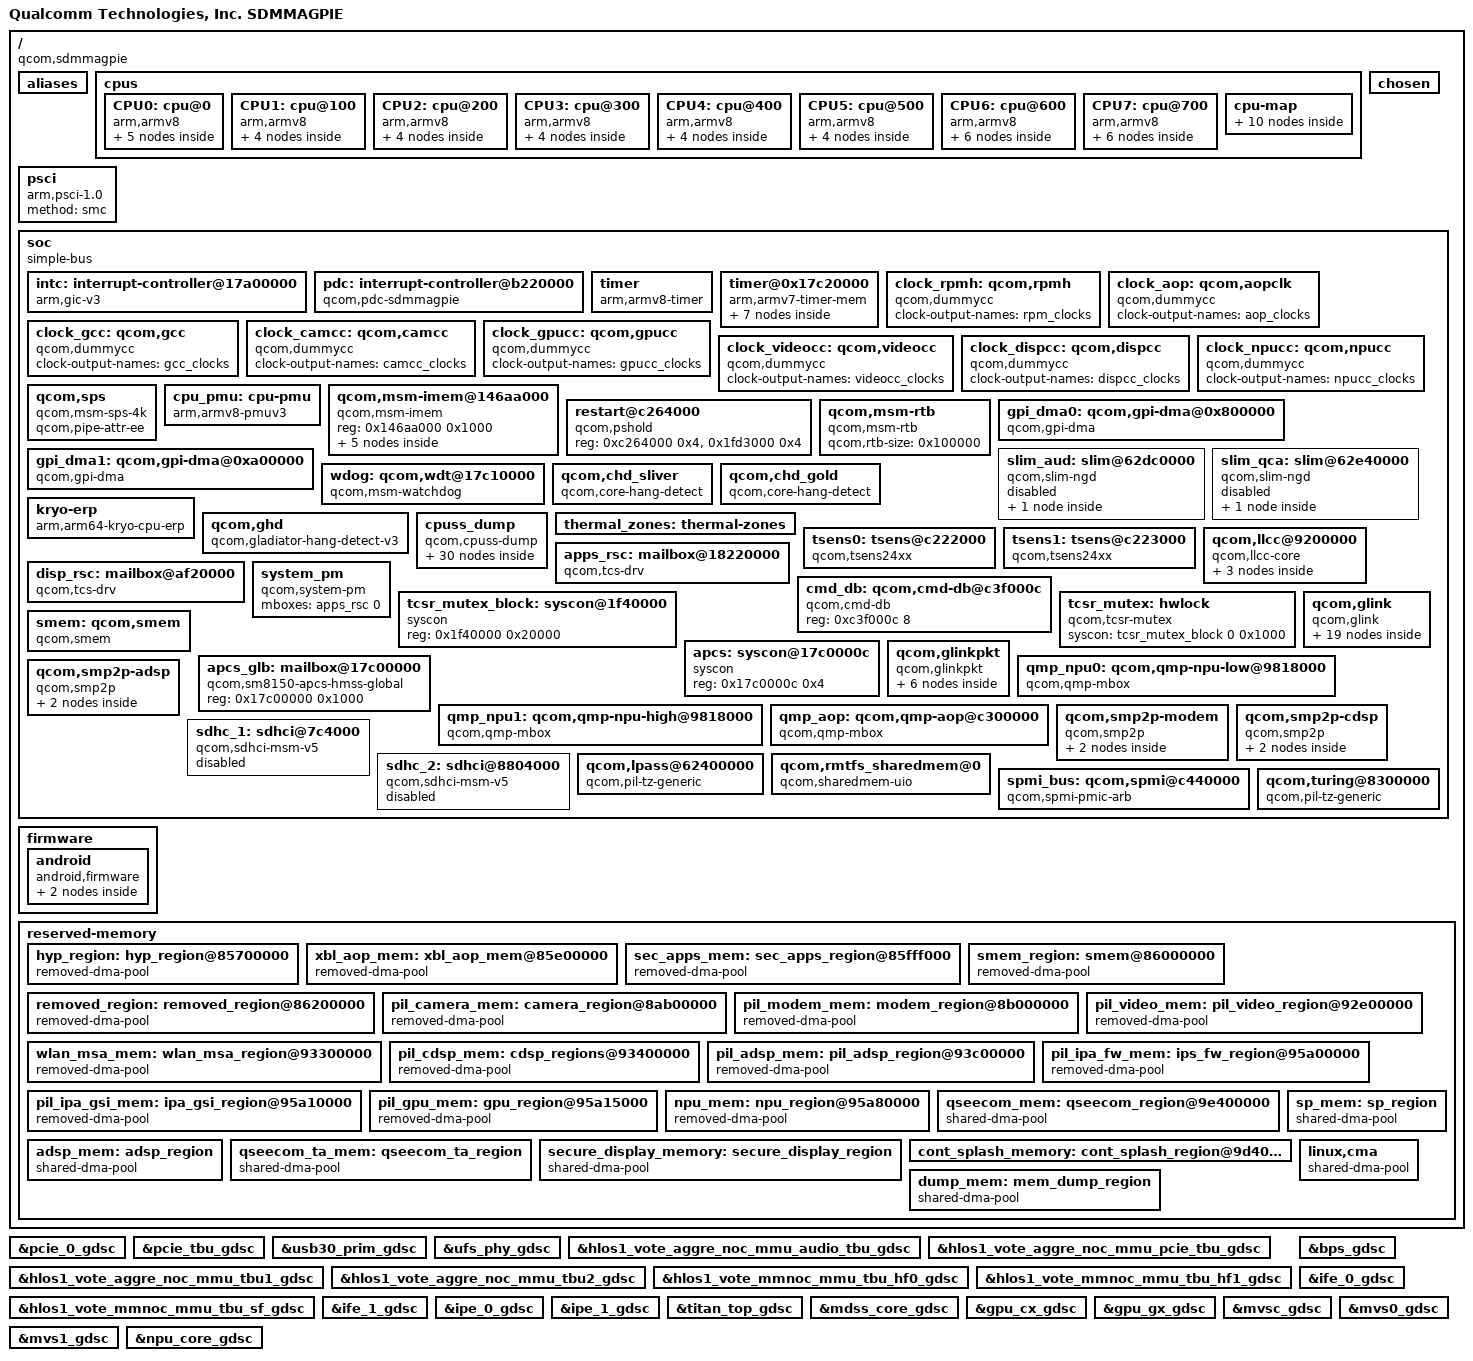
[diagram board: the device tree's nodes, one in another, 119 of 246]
/* Copyright (c) 2018, The Linux Foundation. All rights reserved.
 *
 * This program is free software; you can redistribute it and/or modify
 * it under the terms of the GNU General Public License version 2 and
 * only version 2 as published by the Free Software Foundation.
 *
 * This program is distributed in the hope that it will be useful,
 * but WITHOUT ANY WARRANTY; without even the implied warranty of
 * MERCHANTABILITY or FITNESS FOR A PARTICULAR PURPOSE.  See the
 * GNU General Public License for more details.
 */

#include "skeleton64.dtsi"
#include <dt-bindings/interrupt-controller/arm-gic.h>
#include <dt-bindings/clock/qcom,gcc-sdmmagpie.h>
#include <dt-bindings/clock/qcom,gpucc-sdmmagpie.h>
#include <dt-bindings/clock/qcom,camcc-sdmmagpie.h>
#include <dt-bindings/clock/qcom,videocc-sdmmagpie.h>
#include <dt-bindings/clock/qcom,dispcc-sdmmagpie.h>
#include <dt-bindings/clock/qcom,npucc-sdmmagpie.h>
#include <dt-bindings/clock/qcom,rpmh.h>
#include <dt-bindings/clock/qcom,aop-qmp.h>
#include <dt-bindings/regulator/qcom,rpmh-regulator.h>
#include <dt-bindings/soc/qcom,tcs-mbox.h>

/ {
	model = "Qualcomm Technologies, Inc. SDMMAGPIE";
	compatible = "qcom,sdmmagpie";
	qcom,msm-id = <365 0x0>;
	interrupt-parent = <&pdc>;

	aliases {
		spi0 = &qupv3_se0_spi;
		spi1 = &qupv3_se4_spi;
		i2c0 = &qupv3_se2_i2c;
		i2c1 = &qupv3_se7_i2c;
		i2c2 = &qupv3_se9_i2c;
		serial0 = &qupv3_se8_2uart;
		hsuart0 = &qupv3_se3_4uart;
		sdhc1 = &sdhc_1; /* SDC1 eMMC slot */
		sdhc2 = &sdhc_2; /* SDC2 SD Card slot */
	};

	cpus {
		#address-cells = <2>;
		#size-cells = <0>;

		CPU0: cpu@0 {
			device_type = "cpu";
			compatible = "arm,armv8";
			reg = <0x0 0x0>;
			enable-method = "psci";
			cache-size = <0x8000>;
			next-level-cache = <&L2_0>;
			L2_0: l2-cache {
			      compatible = "arm,arch-cache";
			      cache-size = <0x20000>;
			      cache-level = <2>;
			      next-level-cache = <&L3_0>;

				L3_0: l3-cache {
				      compatible = "arm,arch-cache";
				      cache-size = <0x100000>;
				      cache-level = <3>;
				};
			};

			L1_I_0: l1-icache {
				compatible = "arm,arch-cache";
				qcom,dump-size = <0x8800>;
			};

			L1_D_0: l1-dcache {
				compatible = "arm,arch-cache";
				qcom,dump-size = <0x9000>;
			};

			L2_TLB_0: l2-tlb {
				qcom,dump-size = <0x5000>;
			};
		};

		CPU1: cpu@100 {
			device_type = "cpu";
			compatible = "arm,armv8";
			reg = <0x0 0x100>;
			enable-method = "psci";
			cache-size = <0x8000>;
			next-level-cache = <&L2_100>;
			L2_100: l2-cache {
			      compatible = "arm,arch-cache";
			      cache-size = <0x20000>;
			      cache-level = <2>;
			      next-level-cache = <&L3_0>;
			};

			L1_I_100: l1-icache {
				compatible = "arm,arch-cache";
				qcom,dump-size = <0x8800>;
			};

			L1_D_100: l1-dcache {
				compatible = "arm,arch-cache";
				qcom,dump-size = <0x9000>;
			};

			L2_TLB_100: l2-tlb {
				qcom,dump-size = <0x5000>;
			};
		};


		CPU2: cpu@200 {
			device_type = "cpu";
			compatible = "arm,armv8";
			reg = <0x0 0x200>;
			enable-method = "psci";
			cache-size = <0x8000>;
			next-level-cache = <&L2_200>;
			L2_200: l2-cache {
			      compatible = "arm,arch-cache";
			      cache-size = <0x20000>;
			      cache-level = <2>;
			      next-level-cache = <&L3_0>;
			};

			L1_I_200: l1-icache {
				compatible = "arm,arch-cache";
				qcom,dump-size = <0x8800>;
			};

			L1_D_200: l1-dcache {
				compatible = "arm,arch-cache";
				qcom,dump-size = <0x9000>;
			};

			L2_TLB_200: l2-tlb {
				qcom,dump-size = <0x5000>;
			};
		};

		CPU3: cpu@300 {
			device_type = "cpu";
			compatible = "arm,armv8";
			reg = <0x0 0x300>;
			enable-method = "psci";
			cache-size = <0x8000>;
			next-level-cache = <&L2_300>;
			L2_300: l2-cache {
			      compatible = "arm,arch-cache";
			      cache-size = <0x20000>;
			      cache-level = <2>;
			      next-level-cache = <&L3_0>;
			};

			L1_I_300: l1-icache {
				compatible = "arm,arch-cache";
				qcom,dump-size = <0x8800>;
			};

			L1_D_300: l1-dcache {
				compatible = "arm,arch-cache";
				qcom,dump-size = <0x9000>;
			};

			L2_TLB_300: l2-tlb {
				qcom,dump-size = <0x5000>;
			};
		};

		CPU4: cpu@400 {
			device_type = "cpu";
			compatible = "arm,armv8";
			reg = <0x0 0x400>;
			enable-method = "psci";
			cache-size = <0x8000>;
			next-level-cache = <&L2_400>;
			L2_400: l2-cache {
			      compatible = "arm,arch-cache";
			      cache-size = <0x20000>;
			      cache-level = <2>;
			      next-level-cache = <&L3_0>;
			};

			L1_I_400: l1-icache {
				compatible = "arm,arch-cache";
				qcom,dump-size = <0x8800>;
			};

			L1_D_400: l1-dcache {
				compatible = "arm,arch-cache";
				qcom,dump-size = <0x9000>;
			};

			L2_TLB_400: l2-tlb {
				qcom,dump-size = <0x5000>;
			};
		};

		CPU5: cpu@500 {
			device_type = "cpu";
			compatible = "arm,armv8";
			reg = <0x0 0x500>;
			enable-method = "psci";
			cache-size = <0x8000>;
			next-level-cache = <&L2_500>;
			L2_500: l2-cache {
			      compatible = "arm,arch-cache";
			      cache-size = <0x20000>;
			      cache-level = <2>;
			      next-level-cache = <&L3_0>;
			};

			L1_I_500: l1-icache {
				compatible = "arm,arch-cache";
				qcom,dump-size = <0x8800>;
			};

			L1_D_500: l1-dcache {
				compatible = "arm,arch-cache";
				qcom,dump-size = <0x9000>;
			};

			L2_TLB_500: l2-tlb {
				qcom,dump-size = <0x5000>;
			};
		};

		CPU6: cpu@600 {
			device_type = "cpu";
			compatible = "arm,armv8";
			reg = <0x0 0x600>;
			enable-method = "psci";
			cache-size = <0x10000>;
			next-level-cache = <&L2_600>;
			L2_600: l2-cache {
			      compatible = "arm,arch-cache";
			      cache-size = <0x40000>;
			      cache-level = <2>;
			      next-level-cache = <&L3_0>;
			      qcom,dump-size = <0x48000>;
			};

			L1_I_600: l1-icache {
				compatible = "arm,arch-cache";
				qcom,dump-size = <0x11000>;
			};

			L1_D_600: l1-dcache {
				compatible = "arm,arch-cache";
				qcom,dump-size = <0x12000>;
			};

			L1_ITLB_600: l1-itlb {
				qcom,dump-size = <0x300>;
			};

			L1_DTLB_600: l1-dtlb {
				qcom,dump-size = <0x480>;
			};

			L2_TLB_600: l2-tlb {
				qcom,dump-size = <0x7800>;
			};
		};

		CPU7: cpu@700 {
			device_type = "cpu";
			compatible = "arm,armv8";
			reg = <0x0 0x700>;
			enable-method = "psci";
			cache-size = <0x10000>;
			next-level-cache = <&L2_700>;
			L2_700: l2-cache {
			      compatible = "arm,arch-cache";
			      cache-size = <0x40000>;
			      cache-level = <2>;
			      next-level-cache = <&L3_0>;
			      qcom,dump-size = <0x48000>;
			};

			L1_I_700: l1-icache {
				compatible = "arm,arch-cache";
				qcom,dump-size = <0x11000>;
			};

			L1_D_700: l1-dcache {
				compatible = "arm,arch-cache";
				qcom,dump-size = <0x12000>;
			};

			L1_ITLB_700: l1-itlb {
				qcom,dump-size = <0x300>;
			};

			L1_DTLB_700: l1-dtlb {
				qcom,dump-size = <0x480>;
			};

			L2_TLB_700: l2-tlb {
				qcom,dump-size = <0x7800>;
			};
		};

		cpu-map {
			cluster0 {
				core0 {
					cpu = <&CPU0>;
				};

				core1 {
					cpu = <&CPU1>;
				};

				core2 {
					cpu = <&CPU2>;
				};

				core3 {
					cpu = <&CPU3>;
				};

				core4 {
					cpu = <&CPU4>;
				};

				core5 {
					cpu = <&CPU5>;
				};

			};

			cluster1 {
				core6 {
					cpu = <&CPU6>;
				};

				core7 {
					cpu = <&CPU7>;
				};
			};
		};
	};

	psci {
		compatible = "arm,psci-1.0";
		method = "smc";
	};

	chosen {
		bootargs = "rcupdate.rcu_expedited=1 rcu_nocbs=0-7";
	};

	soc: soc { };

	firmware: firmware {
		android {
			compatible = "android,firmware";
			fstab {
				compatible = "android,fstab";
				vendor {
					compatible = "android,vendor";
					dev = "/dev/block/platform/soc/1d84000.ufshc/by-name/vendor";
					type = "ext4";
					mnt_flags = "ro,barrier=1,discard";
					fsmgr_flags = "wait,slotselect,avb";
					status = "ok";
				};
			};
		};
	};

	reserved-memory {
		#address-cells = <2>;
		#size-cells = <2>;
		ranges;

		hyp_region: hyp_region@85700000 {
			compatible = "removed-dma-pool";
			no-map;
			reg = <0 0x85700000 0 0x600000>;
		};

		xbl_aop_mem: xbl_aop_mem@85e00000 {
			compatible = "removed-dma-pool";
			no-map;
			reg = <0x0 0x85e00000 0x0 0x1ff000>;
		};

		sec_apps_mem: sec_apps_region@85fff000 {
			compatible = "removed-dma-pool";
			no-map;
			reg = <0x0 0x85fff000 0x0 0x1000>;
		};

		smem_region: smem@86000000 {
			compatible = "removed-dma-pool";
			no-map;
			reg = <0x0 0x86000000 0x0 0x200000>;
		};

		removed_region: removed_region@86200000 {
			compatible = "removed-dma-pool";
			no-map;
			reg = <0 0x86200000 0 0x2d00000>;
		};

		pil_camera_mem: camera_region@8ab00000 {
			compatible = "removed-dma-pool";
			no-map;
			reg = <0 0x8ab00000 0 0x500000>;
		};

		pil_modem_mem: modem_region@8b000000 {
			compatible = "removed-dma-pool";
			no-map;
			reg = <0 0x8b000000 0 0x7e00000>;
		};

		pil_video_mem: pil_video_region@92e00000 {
			compatible = "removed-dma-pool";
			no-map;
			reg = <0 0x92e00000 0 0x500000>;
		};

		wlan_msa_mem: wlan_msa_region@93300000 {
			compatible = "removed-dma-pool";
			no-map;
			reg = <0 0x93300000 0 0x100000>;
		};

		pil_cdsp_mem: cdsp_regions@93400000 {
			compatible = "removed-dma-pool";
			no-map;
			reg = <0 0x93400000 0 0x800000>;
		};

		pil_adsp_mem: pil_adsp_region@93c00000 {
			compatible = "removed-dma-pool";
			no-map;
			reg = <0 0x93c00000 0 0x1e00000>;
		};

		pil_ipa_fw_mem: ips_fw_region@95a00000 {
			compatible = "removed-dma-pool";
			no-map;
			reg = <0 0x95a00000 0 0x10000>;
		};

		pil_ipa_gsi_mem: ipa_gsi_region@95a10000 {
			compatible = "removed-dma-pool";
			no-map;
			reg = <0 0x95a10000 0 0x5000>;
		};

		pil_gpu_mem: gpu_region@95a15000 {
			compatible = "removed-dma-pool";
			no-map;
			reg = <0 0x95a15000 0 0x2000>;
		};

		npu_mem: npu_region@95a80000 {
			compatible = "removed-dma-pool";
			no-map;
			reg = <0 0x95a80000 0 0x80000>;
		};

		qseecom_mem: qseecom_region@9e400000 {
			compatible = "shared-dma-pool";
			no-map;
			reg = <0 0x9e400000 0 0x1400000>;
		};

		adsp_mem: adsp_region {
			compatible = "shared-dma-pool";
			alloc-ranges = <0 0x00000000 0 0xffffffff>;
			reusable;
			alignment = <0 0x400000>;
			size = <0 0xc00000>;
		};

		qseecom_ta_mem: qseecom_ta_region {
			compatible = "shared-dma-pool";
			alloc-ranges = <0 0x00000000 0 0xffffffff>;
			reusable;
			alignment = <0 0x400000>;
			size = <0 0x1000000>;
		};

		sp_mem: sp_region {  /* SPSS-HLOS ION shared mem */
			compatible = "shared-dma-pool";
			alloc-ranges = <0 0x00000000 0 0xffffffff>; /* 32-bit */
			reusable;
			alignment = <0 0x400000>;
			size = <0 0x800000>;
		};

		secure_display_memory: secure_display_region {
			compatible = "shared-dma-pool";
			alloc-ranges = <0 0x00000000 0 0xffffffff>;
			reusable;
			alignment = <0 0x400000>;
			size = <0 0x5c00000>;
		};

		cont_splash_memory: cont_splash_region@9d400000 {
			reg = <0x0 0x9d400000 0x0 0x02400000>;
			label = "cont_splash_region";
		};

		dump_mem: mem_dump_region {
			compatible = "shared-dma-pool";
			reusable;
			size = <0 0x2400000>;
		};

		/* global autoconfigured region for contiguous allocations */
		linux,cma {
			compatible = "shared-dma-pool";
			alloc-ranges = <0 0x00000000 0 0xffffffff>;
			reusable;
			alignment = <0 0x400000>;
			size = <0 0x2000000>;
			linux,cma-default;
		};
	};
};

&soc {
	#address-cells = <1>;
	#size-cells = <1>;
	ranges = <0 0 0 0xffffffff>;
	compatible = "simple-bus";

	intc: interrupt-controller@17a00000 {
		compatible = "arm,gic-v3";
		#interrupt-cells = <3>;
		interrupt-controller;
		#redistributor-regions = <1>;
		redistributor-stride = <0x0 0x20000>;
		reg = <0x17a00000 0x10000>,     /* GICD */
		      <0x17a60000 0x100000>;    /* GICR * 8 */
		interrupts = <GIC_PPI 9 IRQ_TYPE_LEVEL_HIGH>;
		interrupt-parent = <&intc>;
	};

	pdc: interrupt-controller@b220000 {
		compatible = "qcom,pdc-sdmmagpie";
		reg = <0xb220000 0x400>;
		#interrupt-cells = <3>;
		interrupt-parent = <&intc>;
		interrupt-controller;
	};

	timer {
		compatible = "arm,armv8-timer";
		interrupts = <GIC_PPI 1 0xf08>,
			     <GIC_PPI 2 0xf08>,
			     <GIC_PPI 3 0xf08>,
			     <GIC_PPI 0 0xf08>;
		clock-frequency = <19200000>;
	};

	timer@0x17c20000{
		#address-cells = <1>;
		#size-cells = <1>;
		ranges;
		compatible = "arm,armv7-timer-mem";
		reg = <0x17c20000 0x1000>;
		clock-frequency = <19200000>;

		frame@0x17c21000 {
			frame-number = <0>;
			interrupts = <GIC_SPI 8 IRQ_TYPE_LEVEL_HIGH>,
				     <GIC_SPI 6 IRQ_TYPE_LEVEL_HIGH>;
			reg = <0x17c21000 0x1000>,
			      <0x17c22000 0x1000>;
		};

		frame@17c23000 {
			frame-number = <1>;
			interrupts = <GIC_SPI 9 IRQ_TYPE_LEVEL_HIGH>;
			reg = <0x17c23000 0x1000>;
			status = "disabled";
		};

		frame@17c25000 {
			frame-number = <2>;
			interrupts = <GIC_SPI 10 IRQ_TYPE_LEVEL_HIGH>;
			reg = <0x17c25000 0x1000>;
			status = "disabled";
		};

		frame@17c27000 {
			frame-number = <3>;
			interrupts = <GIC_SPI 11 IRQ_TYPE_LEVEL_HIGH>;
			reg = <0x17c27000 0x1000>;
			status = "disabled";
		};

		frame@17c29000 {
			frame-number = <4>;
			interrupts = <GIC_SPI 12 IRQ_TYPE_LEVEL_HIGH>;
			reg = <0x17c29000 0x1000>;
			status = "disabled";
		};

		frame@17c2b000 {
			frame-number = <5>;
			interrupts = <GIC_SPI 13 IRQ_TYPE_LEVEL_HIGH>;
			reg = <0x17c2b000 0x1000>;
			status = "disabled";
		};

		frame@17c2d000 {
			frame-number = <6>;
			interrupts = <GIC_SPI 14 IRQ_TYPE_LEVEL_HIGH>;
			reg = <0x17c2d000 0x1000>;
			status = "disabled";
		};
	};

	clock_rpmh: qcom,rpmh {
		compatible = "qcom,dummycc";
		clock-output-names = "rpm_clocks";
		#clock-cells = <1>;
	};

	clock_aop: qcom,aopclk {
		compatible = "qcom,dummycc";
		clock-output-names = "aop_clocks";
		#clock-cells = <1>;
	};

	clock_gcc: qcom,gcc {
		compatible = "qcom,dummycc";
		clock-output-names = "gcc_clocks";
		#clock-cells = <1>;
		#reset-cells = <1>;
	};

	clock_camcc: qcom,camcc {
		compatible = "qcom,dummycc";
		clock-output-names = "camcc_clocks";
		#clock-cells = <1>;
		#reset-cells = <1>;
	};

	clock_gpucc: qcom,gpucc {
		compatible = "qcom,dummycc";
		clock-output-names = "gpucc_clocks";
		#clock-cells = <1>;
		#reset-cells = <1>;
	};

	clock_videocc: qcom,videocc {
		compatible = "qcom,dummycc";
		clock-output-names = "videocc_clocks";
		#clock-cells = <1>;
		#reset-cells = <1>;
	};

	clock_dispcc: qcom,dispcc {
		compatible = "qcom,dummycc";
		clock-output-names = "dispcc_clocks";
		#clock-cells = <1>;
		#reset-cells = <1>;
	};

	clock_npucc: qcom,npucc {
		compatible = "qcom,dummycc";
		clock-output-names = "npucc_clocks";
		#clock-cells = <1>;
		#reset-cells = <1>;
	};

	qcom,sps {
		compatible = "qcom,msm-sps-4k";
		qcom,pipe-attr-ee;
	};

	cpu_pmu: cpu-pmu {
		compatible = "arm,armv8-pmuv3";
		qcom,irq-is-percpu;
		interrupts = <GIC_PPI 5 IRQ_TYPE_LEVEL_HIGH>;
	};

	qcom,msm-imem@146aa000 {
		compatible = "qcom,msm-imem";
		reg = <0x146aa000 0x1000>;
		ranges = <0x0 0x146aa000 0x1000>;
		#address-cells = <1>;
		#size-cells = <1>;

		mem_dump_table@10 {
			compatible = "qcom,msm-imem-mem_dump_table";
			reg = <0x10 8>;
		};

		restart_reason@65c {
			compatible = "qcom,msm-imem-restart_reason";
			reg = <0x65c 4>;
		};

		boot_stats@6b0 {
			compatible = "qcom,msm-imem-boot_stats";
			reg = <0x6b0 32>;
		};

		kaslr_offset@6d0 {
			compatible = "qcom,msm-imem-kaslr_offset";
			reg = <0x6d0 12>;
		};

		pil@94c {
			compatible = "qcom,msm-imem-pil";
			reg = <0x94c 200>;
		};
	};

	restart@c264000 {
		compatible = "qcom,pshold";
		reg = <0xc264000 0x4>,
		      <0x1fd3000 0x4>;
		reg-names = "pshold-base", "tcsr-boot-misc-detect";
	};

	qcom,msm-rtb {
		compatible = "qcom,msm-rtb";
		qcom,rtb-size = <0x100000>;
	};

	gpi_dma0: qcom,gpi-dma@0x800000 {
		#dma-cells = <5>;
		compatible = "qcom,gpi-dma";
		reg = <0x800000 0x60000>;
		reg-names = "gpi-top";
		interrupts = <0 244 0>, <0 245 0>, <0 246 0>, <0 247 0>,
			     <0 248 0>, <0 249 0>, <0 250 0>, <0 251 0>;
		qcom,max-num-gpii = <8>;
		qcom,gpii-mask = <0x0f>;
		qcom,ev-factor = <2>;
		iommus = <&apps_smmu 0x0216 0x0>;
		qcom,smmu-cfg = <0x1>;
		qcom,iova-range = <0x0 0x100000 0x0 0x100000>;
		status = "ok";
	};

	gpi_dma1: qcom,gpi-dma@0xa00000 {
		#dma-cells = <5>;
		compatible = "qcom,gpi-dma";
		reg = <0xa00000 0x60000>;
		reg-names = "gpi-top";
		interrupts = <0 279 0>, <0 280 0>, <0 281 0>, <0 282 0>,
		     <0 283 0>, <0 284 0>, <0 293 0>, <0 294 0>;
		qcom,max-num-gpii = <8>;
		qcom,gpii-mask = <0x0f>;
		qcom,ev-factor = <2>;
		iommus = <&apps_smmu 0x04d6 0x0>;
		qcom,smmu-cfg = <0x1>;
		qcom,iova-range = <0x0 0x100000 0x0 0x100000>;
		status = "ok";
	};

	slim_aud: slim@62dc0000 {
		cell-index = <1>;
		compatible = "qcom,slim-ngd";
		reg = <0x62dc0000 0x2c000>,
			<0x62d84000 0x2a000>;
		reg-names = "slimbus_physical", "slimbus_bam_physical";
		interrupts = <0 163 0>, <0 164 0>;
		interrupt-names = "slimbus_irq", "slimbus_bam_irq";
		qcom,apps-ch-pipes = <0x7c0000>;
		qcom,ea-pc = <0x300>;
		status = "disabled";
		qcom,iommu-s1-bypass;

		iommu_slim_aud_ctrl_cb: qcom,iommu_slim_ctrl_cb {
			compatible = "qcom,iommu-slim-ctrl-cb";
			iommus = <&apps_smmu 0x1be6 0x0>,
				 <&apps_smmu 0x1bed 0x0>,
				 <&apps_smmu 0x1bee 0x1>,
				 <&apps_smmu 0x1bf0 0x1>;
		};

	};

	slim_qca: slim@62e40000 {
		cell-index = <3>;
		compatible = "qcom,slim-ngd";
		reg = <0x62e40000 0x2c000>,
			<0x62e04000 0x20000>;
		reg-names = "slimbus_physical", "slimbus_bam_physical";
		interrupts = <0 291 0>, <0 292 0>;
		interrupt-names = "slimbus_irq", "slimbus_bam_irq";
		status = "disabled";
		qcom,iommu-s1-bypass;

		iommu_slim_qca_ctrl_cb: qcom,iommu_slim_ctrl_cb {
			compatible = "qcom,iommu-slim-ctrl-cb";
			iommus = <&apps_smmu 0x1bf3 0x0>;
		};
	};

	wdog: qcom,wdt@17c10000{
		compatible = "qcom,msm-watchdog";
		reg = <0x17c10000 0x1000>;
		reg-names = "wdt-base";
		interrupts = <GIC_SPI 0 IRQ_TYPE_NONE>,
			     <GIC_SPI 1 IRQ_TYPE_NONE>;
		qcom,bark-time = <11000>;
		qcom,pet-time = <9360>;
		qcom,ipi-ping;
		qcom,wakeup-enable;
	};

	qcom,chd_sliver {
		compatible = "qcom,core-hang-detect";
		label = "silver";
		qcom,threshold-arr = <0x18000058 0x18010058
				      0x18020058 0x18030058
				      0x18040058 0x18050058>;
		qcom,config-arr = <0x18000060 0x18010060
				   0x18020060 0x18030060
				   0x18040060 0x18050060>;
	};

	qcom,chd_gold {
		compatible = "qcom,core-hang-detect";
		label = "gold";
		qcom,threshold-arr = <0x18060058 0x18070058>;
		qcom,config-arr = <0x18060060 0x18070060>;
	};

	kryo-erp {
		compatible = "arm,arm64-kryo-cpu-erp";
		interrupts = <GIC_PPI 6 IRQ_TYPE_LEVEL_HIGH>,
			     <GIC_SPI 35 IRQ_TYPE_LEVEL_HIGH>;

		interrupt-names = "l1-l2-faultirq",
				  "l3-scu-faultirq";
	};

	qcom,ghd {
		compatible = "qcom,gladiator-hang-detect-v3";
		qcom,threshold-arr = <0x17e0041C>;
		qcom,config-reg = <0x17e00434>;
	};

	cpuss_dump {
		compatible = "qcom,cpuss-dump";

		qcom,l1_i_cache0 {
			qcom,dump-node = <&L1_I_0>;
			qcom,dump-id = <0x60>;
		};

		qcom,l1_i_cache100 {
			qcom,dump-node = <&L1_I_100>;
			qcom,dump-id = <0x61>;
		};

		qcom,l1_i_cache200 {
			qcom,dump-node = <&L1_I_200>;
			qcom,dump-id = <0x62>;
		};

		qcom,l1_i_cache300 {
			qcom,dump-node = <&L1_I_300>;
			qcom,dump-id = <0x63>;
		};

		qcom,l1_i_cache400 {
			qcom,dump-node = <&L1_I_400>;
			qcom,dump-id = <0x64>;
		};

		qcom,l1_i_cache500 {
			qcom,dump-node = <&L1_I_500>;
			qcom,dump-id = <0x65>;
		};

		qcom,l1_i_cache600 {
			qcom,dump-node = <&L1_I_600>;
			qcom,dump-id = <0x66>;
		};

		qcom,l1_i_cache700 {
			qcom,dump-node = <&L1_I_700>;
			qcom,dump-id = <0x67>;
		};

		qcom,l1_d_cache0 {
			qcom,dump-node = <&L1_D_0>;
			qcom,dump-id = <0x80>;
		};

		qcom,l1_d_cache100 {
			qcom,dump-node = <&L1_D_100>;
			qcom,dump-id = <0x81>;
		};

		qcom,l1_d_cache200 {
			qcom,dump-node = <&L1_D_200>;
			qcom,dump-id = <0x82>;
		};

		qcom,l1_d_cache300 {
			qcom,dump-node = <&L1_D_300>;
			qcom,dump-id = <0x83>;
		};

		qcom,l1_d_cache400 {
			qcom,dump-node = <&L1_D_400>;
			qcom,dump-id = <0x84>;
		};

		qcom,l1_d_cache500 {
			qcom,dump-node = <&L1_D_500>;
			qcom,dump-id = <0x85>;
		};

		qcom,l1_d_cache600 {
			qcom,dump-node = <&L1_D_600>;
			qcom,dump-id = <0x86>;
		};

		qcom,l1_d_cache700 {
			qcom,dump-node = <&L1_D_700>;
			qcom,dump-id = <0x87>;
		};

		qcom,l1_i_tlb_dump600 {
			qcom,dump-node = <&L1_ITLB_600>;
			qcom,dump-id = <0x26>;
		};

		qcom,l1_i_tlb_dump700 {
			qcom,dump-node = <&L1_ITLB_700>;
			qcom,dump-id = <0x27>;
		};

		qcom,l1_d_tlb_dump600 {
			qcom,dump-node = <&L1_DTLB_600>;
			qcom,dump-id = <0x46>;
		};

		qcom,l1_d_tlb_dump700 {
			qcom,dump-node = <&L1_DTLB_700>;
			qcom,dump-id = <0x47>;
		};

		qcom,l2_cache_dump600 {
			qcom,dump-node = <&L2_600>;
			qcom,dump-id = <0xc6>;
		};

		qcom,l2_cache_dump700 {
			qcom,dump-node = <&L2_700>;
			qcom,dump-id = <0xc7>;
		};

		qcom,l2_tlb_dump0 {
			qcom,dump-node = <&L2_TLB_0>;
			qcom,dump-id = <0x120>;
		};

		qcom,l2_tlb_dump100 {
			qcom,dump-node = <&L2_TLB_100>;
			qcom,dump-id = <0x121>;
		};

		qcom,l2_tlb_dump200 {
			qcom,dump-node = <&L2_TLB_200>;
			qcom,dump-id = <0x122>;
		};

		qcom,l2_tlb_dump300 {
			qcom,dump-node = <&L2_TLB_300>;
			qcom,dump-id = <0x123>;
		};

		qcom,l2_tlb_dump400 {
			qcom,dump-node = <&L2_TLB_400>;
			qcom,dump-id = <0x124>;
		};

		qcom,l2_tlb_dump500 {
			qcom,dump-node = <&L2_TLB_500>;
			qcom,dump-id = <0x125>;
		};

		qcom,l2_tlb_dump600 {
			qcom,dump-node = <&L2_TLB_600>;
			qcom,dump-id = <0x126>;
		};

		qcom,l2_tlb_dump700 {
			qcom,dump-node = <&L2_TLB_700>;
			qcom,dump-id = <0x127>;
		};
	};

	thermal_zones: thermal-zones {};

	tsens0: tsens@c222000 {
		compatible = "qcom,tsens24xx";
		reg = <0xc222000 0x8>,
		      <0xc263000 0x1ff>;
		reg-names = "tsens_srot_physical",
			    "tsens_tm_physical";
		interrupts = <0 506 0>, <0 508 0>;
		interrupt-names = "tsens-upper-lower", "tsens-critical";
		#thermal-sensor-cells = <1>;
	};

	tsens1: tsens@c223000 {
		compatible = "qcom,tsens24xx";
		reg = <0xc223000 0x8>,
		      <0xc265000 0x1ff>;
		reg-names = "tsens_srot_physical",
			    "tsens_tm_physical";
		interrupts = <0 507 0>, <0 509 0>;
		interrupt-names = "tsens-upper-lower", "tsens-critical";
		#thermal-sensor-cells = <1>;
	};

	qcom,llcc@9200000 {
		compatible = "qcom,llcc-core", "syscon", "simple-mfd";
		reg = <0x9200000 0x450000>;
		reg-names = "llcc_base";
		qcom,llcc-banks-off = <0x0 0x80000>;
		qcom,llcc-broadcast-off = <0x400000>;

		llcc: qcom,sdmmagpie-llcc {
			compatible = "qcom,sdmmagpie-llcc";
			#cache-cells = <1>;
			max-slices = <32>;
			cap-based-alloc-and-pwr-collapse;
		};

		qcom,llcc-erp {
			compatible = "qcom,llcc-erp";
			interrupt-names = "ecc_irq";
			interrupts = <GIC_SPI 582 IRQ_TYPE_LEVEL_HIGH>;
		};

		qcom,llcc-amon {
			compatible = "qcom,llcc-amon";
		};
	};

	apps_rsc: mailbox@18220000 {
		compatible = "qcom,tcs-drv";
		label = "apps_rsc";
		reg = <0x18220000 0x100>, <0x18220d00 0x3000>;
		interrupts = <0 5 0>;
		#mbox-cells = <1>;
		qcom,drv-id = <2>;
		qcom,tcs-config = <ACTIVE_TCS  2>,
				  <SLEEP_TCS   3>,
				  <WAKE_TCS    3>,
				  <CONTROL_TCS 1>;
	};

	disp_rsc: mailbox@af20000 {
		compatible = "qcom,tcs-drv";
		label = "display_rsc";
		reg = <0xaf20000 0x100>, <0xaf21c00 0x3000>;
		interrupts = <0 129 0>;
		#mbox-cells = <1>;
		qcom,drv-id = <0>;
		qcom,tcs-config = <ACTIVE_TCS  2>,
				  <SLEEP_TCS   1>,
				  <WAKE_TCS    1>,
				  <CONTROL_TCS 0>;
	};

	system_pm {
		compatible = "qcom,system-pm";
		mboxes = <&apps_rsc 0>;
	};

	cmd_db: qcom,cmd-db@c3f000c {
		compatible = "qcom,cmd-db";
		reg = <0xc3f000c 8>;
	};

	tcsr_mutex_block: syscon@1f40000 {
		compatible = "syscon";
		reg = <0x1f40000 0x20000>;
	};

	tcsr_mutex: hwlock {
		compatible = "qcom,tcsr-mutex";
		syscon = <&tcsr_mutex_block 0 0x1000>;
		#hwlock-cells = <1>;
	};

	smem: qcom,smem {
		compatible = "qcom,smem";
		memory-region = <&smem_region>;
		hwlocks = <&tcsr_mutex 3>;
	};

	apcs: syscon@17c0000c {
		compatible = "syscon";
		reg = <0x17c0000c 0x4>;
	};

	apcs_glb: mailbox@17c00000 {
		compatible = "qcom,sm8150-apcs-hmss-global";
		reg = <0x17c00000 0x1000>;

		#mbox-cells = <1>;
	};

	qcom,glink {
		compatible = "qcom,glink";
		#address-cells = <1>;
		#size-cells = <1>;
		ranges;

		glink_modem: modem {
			qcom,remote-pid = <1>;
			transport = "smem";
			mboxes = <&apcs_glb 12>;
			mbox-names = "mpss_smem";
			interrupts = <GIC_SPI 449 IRQ_TYPE_EDGE_RISING>;

			label = "modem";
			qcom,glink-label = "mpss";

			qcom,modem_qrtr {
				qcom,glink-channels = "IPCRTR";
				qcom,intents = <0x800  5
						0x2000 3
						0x4400 2>;
			};

			qcom,msm_fastrpc_rpmsg {
				compatible = "qcom,msm-fastrpc-rpmsg";
				qcom,glink-channels = "fastrpcglink-apps-dsp";
				qcom,intents = <0x64 64>;
			};

			qcom,modem_ds {
				qcom,glink-channels = "DS";
				qcom,intents = <0x4000 0x2>;
			};

			qcom,modem_glink_ssr {
				qcom,glink-channels = "glink_ssr";
				qcom,notify-edges = <&glink_adsp>,
						    <&glink_cdsp>;
			};
		};

		glink_adsp: adsp {
			qcom,remote-pid = <2>;
			transport = "smem";
			mboxes = <&apcs_glb 24>;
			mbox-names = "adsp_smem";
			interrupts = <GIC_SPI 170 IRQ_TYPE_EDGE_RISING>;

			label = "adsp";
			qcom,glink-label = "lpass";

			qcom,adsp_qrtr {
				qcom,glink-channels = "IPCRTR";
				qcom,intents = <0x800  5
						0x2000 3
						0x4400 2>;
			};

			qcom,apr_tal_rpmsg {
				qcom,glink-channels = "apr_audio_svc";
				qcom,intents = <0x200 20>;
			};

			qcom,msm_fastrpc_rpmsg {
				compatible = "qcom,msm-fastrpc-rpmsg";
				qcom,glink-channels = "fastrpcglink-apps-dsp";
				qcom,intents = <0x64 64>;
			};

			qcom,adsp_glink_ssr {
				qcom,glink-channels = "glink_ssr";
				qcom,notify-edges = <&glink_modem>,
						    <&glink_cdsp>;
			};
		};

		glink_cdsp: cdsp {
			qcom,remote-pid = <5>;
			transport = "smem";
			mboxes = <&apcs_glb 4>;
			mbox-names = "cdsp_smem";
			interrupts = <GIC_SPI 574 IRQ_TYPE_EDGE_RISING>;

			label = "cdsp";
			qcom,glink-label = "cdsp";

			qcom,cdsp_qrtr {
				qcom,glink-channels = "IPCRTR";
				qcom,intents = <0x800  5
						0x2000 3
						0x4400 2>;
			};

			qcom,msm_fastrpc_rpmsg {
				compatible = "qcom,msm-fastrpc-rpmsg";
				qcom,glink-channels = "fastrpcglink-apps-dsp";
				qcom,intents = <0x64 64>;
			};

			qcom,cdsp_glink_ssr {
				qcom,glink-channels = "glink_ssr";
				qcom,notify-edges = <&glink_modem>,
						    <&glink_adsp>;
			};
		};

		glink_spi_xprt_wdsp: wdsp {
			qcom,remote-pid = <10>;
			transport = "spi";
			tx-descriptors = <0x12000 0x12004>;
			rx-descriptors = <0x1200c 0x12010>;

			qcom,wdsp_ctrl {
				qcom,glink-channels = "g_glink_ctrl";
				qcom,intents = <0x400 1>;
			};

			qcom,wdsp_ild {
				qcom,glink-channels =
					"g_glink_persistent_data_ild";
			};

			qcom,wdsp_nild {
				qcom,glink-channels =
					"g_glink_persistent_data_nild";
			};

			qcom,wdsp_data {
				qcom,glink-channels = "g_glink_audio_data";
				qcom,intents = <0x1000 2>;
			};
		};
	};

	qcom,glinkpkt {
		compatible = "qcom,glinkpkt";

		qcom,glinkpkt-at-mdm0 {
			qcom,glinkpkt-edge = "mpss";
			qcom,glinkpkt-ch-name = "DS";
			qcom,glinkpkt-dev-name = "at_mdm0";
		};

		qcom,glinkpkt-apr-apps2 {
			qcom,glinkpkt-edge = "adsp";
			qcom,glinkpkt-ch-name = "apr_apps2";
			qcom,glinkpkt-dev-name = "apr_apps2";
		};

		qcom,glinkpkt-data40-cntl {
			qcom,glinkpkt-edge = "mpss";
			qcom,glinkpkt-ch-name = "DATA40_CNTL";
			qcom,glinkpkt-dev-name = "smdcntl8";
		};

		qcom,glinkpkt-data1 {
			qcom,glinkpkt-edge = "mpss";
			qcom,glinkpkt-ch-name = "DATA1";
			qcom,glinkpkt-dev-name = "smd7";
		};

		qcom,glinkpkt-data4 {
			qcom,glinkpkt-edge = "mpss";
			qcom,glinkpkt-ch-name = "DATA4";
			qcom,glinkpkt-dev-name = "smd8";
		};

		qcom,glinkpkt-data11 {
			qcom,glinkpkt-edge = "mpss";
			qcom,glinkpkt-ch-name = "DATA11";
			qcom,glinkpkt-dev-name = "smd11";
		};
	};

	qmp_npu0: qcom,qmp-npu-low@9818000 {
		compatible = "qcom,qmp-mbox";
		reg = <0x9818000 0x8000>, <0x17c00010 0x4>;
		reg-names = "msgram", "irq-reg-base";
		qcom,irq-mask = <0x20>;
		interrupts = <GIC_SPI 588 IRQ_TYPE_EDGE_RISING>;

		label = "npu_qmp_low";
		priority = <0>;
		mbox-desc-offset = <0x0>;
		#mbox-cells = <1>;
	};

	qmp_npu1: qcom,qmp-npu-high@9818000 {
		compatible = "qcom,qmp-mbox";
		reg = <0x9818000 0x8000>, <0x17c00010 0x4>;
		reg-names = "msgram", "irq-reg-base";
		qcom,irq-mask = <0x40>;
		interrupts = <GIC_SPI 589 IRQ_TYPE_EDGE_RISING>;

		label = "npu_qmp_high";
		priority = <1>;
		mbox-desc-offset = <0x2000>;
		#mbox-cells = <1>;
	};

	qmp_aop: qcom,qmp-aop@c300000 {
		compatible = "qcom,qmp-mbox";
		reg = <0xc300000 0x1000>, <0x17c0000C 0x4>;
		reg-names = "msgram", "irq-reg-base";
		qcom,irq-mask = <0x1>;
		interrupts = <GIC_SPI 389 IRQ_TYPE_EDGE_RISING>;

		label = "aop";
		qcom,early-boot;
		priority = <0>;
		mbox-desc-offset = <0x0>;
		#mbox-cells = <1>;
	};

	qcom,smp2p-modem {
		compatible = "qcom,smp2p";
		qcom,smem = <435>, <428>;
		interrupts = <GIC_SPI 451 IRQ_TYPE_EDGE_RISING>;
		qcom,ipc = <&apcs 0 14>;
		qcom,local-pid = <0>;
		qcom,remote-pid = <1>;

		modem_smp2p_out: master-kernel {
			qcom,entry-name = "master-kernel";
			#qcom,smem-state-cells = <1>;
		};

		modem_smp2p_in: slave-kernel {
			qcom,entry-name = "slave-kernel";
			interrupt-controller;
			#interrupt-cells = <2>;
		};
	};

	qcom,smp2p-adsp {
		compatible = "qcom,smp2p";
		qcom,smem = <443>, <429>;
		interrupts = <GIC_SPI 172 IRQ_TYPE_EDGE_RISING>;
		qcom,ipc = <&apcs 0 26>;
		qcom,local-pid = <0>;
		qcom,remote-pid = <2>;

		adsp_smp2p_out: master-kernel {
			qcom,entry-name = "master-kernel";
			#qcom,smem-state-cells = <1>;
		};

		adsp_smp2p_in: slave-kernel {
			qcom,entry-name = "slave-kernel";
			interrupt-controller;
			#interrupt-cells = <2>;
		};
	};

	qcom,smp2p-cdsp {
		compatible = "qcom,smp2p";
		qcom,smem = <94>, <432>;
		interrupts = <GIC_SPI 576 IRQ_TYPE_EDGE_RISING>;
		qcom,ipc = <&apcs 0 6>;
		qcom,local-pid = <0>;
		qcom,remote-pid = <5>;

		cdsp_smp2p_out: master-kernel {
			qcom,entry-name = "master-kernel";
			#qcom,smem-state-cells = <1>;
		};

		cdsp_smp2p_in: slave-kernel {
			qcom,entry-name = "slave-kernel";
			interrupt-controller;
			#interrupt-cells = <2>;
		};
	};

	sdhc_1: sdhci@7c4000 {
		compatible = "qcom,sdhci-msm-v5";
		reg = <0x7c4000 0x1000>, <0x7c5000 0x1000>;
		reg-names = "hc_mem", "cmdq_mem";

		interrupts = <IRQ_TYPE_NONE 641 IRQ_TYPE_NONE>,
					<IRQ_TYPE_NONE 644 IRQ_TYPE_NONE>;
		interrupt-names = "hc_irq", "pwr_irq";

		qcom,bus-width = <8>;
		qcom,large-address-bus;

		qcom,clk-rates = <400000 20000000 25000000 50000000 100000000
						192000000 384000000>;
		qcom,bus-speed-mode = "HS400_1p8v", "HS200_1p8v", "DDR_1p8v";

		qcom,devfreq,freq-table = <50000000 200000000>;

		clocks = <&clock_gcc GCC_SDCC1_AHB_CLK>,
			<&clock_gcc GCC_SDCC1_APPS_CLK>;
		clock-names = "iface_clk", "core_clk";

		qcom,nonremovable;
		status = "disabled";
	};

	sdhc_2: sdhci@8804000 {
		compatible = "qcom,sdhci-msm-v5";
		reg = <0x8804000 0x1000>;
		reg-names = "hc_mem";

		interrupts = <IRQ_TYPE_NONE 204 IRQ_TYPE_NONE>,
					<IRQ_TYPE_NONE 222 IRQ_TYPE_NONE>;
		interrupt-names = "hc_irq", "pwr_irq";

		qcom,bus-width = <4>;
		qcom,large-address-bus;

		qcom,clk-rates = <400000 20000000 25000000
				50000000 100000000 201500000>;
		qcom,bus-speed-mode = "SDR12", "SDR25", "SDR50", "DDR50",
				      "SDR104";

		qcom,devfreq,freq-table = <50000000 201500000>;

		clocks = <&clock_gcc GCC_SDCC2_AHB_CLK>,
			<&clock_gcc GCC_SDCC2_APPS_CLK>;
		clock-names = "iface_clk", "core_clk";

		status = "disabled";
	};

	qcom,lpass@62400000 {
		compatible = "qcom,pil-tz-generic";
		reg = <0x62400000 0x00100>;

		vdd_lpi_cx-supply = <&L8A_LEVEL>;
		qcom,vdd_cx-uV-uA = <RPMH_REGULATOR_LEVEL_TURBO 0>;
		vdd_lpi_mx-supply = <&L7A_LEVEL>;
		qcom,vdd_mx-uV-uA = <RPMH_REGULATOR_LEVEL_TURBO 0>;
		qcom,proxy-reg-names = "vdd_lpi_cx", "vdd_lpi_mx";

		clocks = <&clock_rpmh RPMH_CXO_CLK>;
		clock-names = "xo";
		qcom,proxy-clock-names = "xo";

		qcom,pas-id = <1>;
		qcom,proxy-timeout-ms = <10000>;
		qcom,smem-id = <423>;
		qcom,sysmon-id = <1>;
		qcom,ssctl-instance-id = <0x14>;
		qcom,firmware-name = "adsp";
		memory-region = <&pil_adsp_mem>;

		/* Inputs from lpass */
		interrupts-extended = <&pdc GIC_SPI 162 IRQ_TYPE_EDGE_RISING>,
				      <&adsp_smp2p_in 0 0>,
				      <&adsp_smp2p_in 1 0>,
				      <&adsp_smp2p_in 2 0>,
				      <&adsp_smp2p_in 3 0>;

		interrupt-names = "qcom,wdog",
				  "qcom,err-fatal",
				  "qcom,err-ready",
				  "qcom,proxy-unvote",
				  "qcom,stop-ack";

		/* Outputs to lpass */
		qcom,smem-states = <&adsp_smp2p_out 0>;
		qcom,smem-state-names = "qcom,force-stop";

		mboxes = <&qmp_aop 0>;
		mbox-names = "adsp-pil";
	};

	qcom,rmtfs_sharedmem@0 {
		compatible = "qcom,sharedmem-uio";
		reg = <0x0 0x200000>;
		reg-names = "rmtfs";
		qcom,client-id = <0x00000001>;
		qcom,guard-memory;
	};

	spmi_bus: qcom,spmi@c440000 {
		compatible = "qcom,spmi-pmic-arb";
		reg = <0xc440000 0x2300>,
			<0xc600000 0x2000000>,
			<0xe600000 0x100000>,
			<0xe700000 0xa0000>,
			<0xc40a000 0x26000>;
		reg-names = "core", "chnls", "obsrvr", "intr", "cnfg";
		interrupt-names = "periph_irq";
		interrupts = <GIC_SPI 481 IRQ_TYPE_NONE>;
		qcom,ee = <0>;
		qcom,channel = <0>;
		#address-cells = <2>;
		#size-cells = <0>;
		interrupt-controller;
		#interrupt-cells = <4>;
		cell-index = <0>;
	};

	qcom,turing@8300000 {
		compatible = "qcom,pil-tz-generic";
		reg = <0x8300000 0x100000>;

		vdd_cx-supply = <&VDD_CX_LEVEL>;
		qcom,vdd_cx-uV-uA = <RPMH_REGULATOR_LEVEL_TURBO 100000>;
		vdd_mx-supply = <&VDD_MX_LEVEL>;
		qcom,vdd_mx-uV-uA = <RPMH_REGULATOR_LEVEL_TURBO 100000>;
		qcom,proxy-reg-names = "vdd_cx", "vdd_mx";

		clocks = <&clock_rpmh RPMH_CXO_CLK>;
		clock-names = "xo";
		qcom,proxy-clock-names = "xo";

		qcom,pas-id = <18>;
		qcom,proxy-timeout-ms = <10000>;
		qcom,smem-id = <601>;
		qcom,sysmon-id = <7>;
		qcom,ssctl-instance-id = <0x17>;
		qcom,firmware-name = "cdsp";
		memory-region = <&pil_cdsp_mem>;

		/* Inputs from turing */
		interrupts-extended = <&pdc GIC_SPI 578 IRQ_TYPE_EDGE_RISING>,
				      <&cdsp_smp2p_in 0 0>,
				      <&cdsp_smp2p_in 1 0>,
				      <&cdsp_smp2p_in 2 0>,
				      <&cdsp_smp2p_in 3 0>;

		interrupt-names = "qcom,wdog",
				  "qcom,err-fatal",
				  "qcom,err-ready",
				  "qcom,proxy-unvote",
				  "qcom,stop-ack";

		/* Outputs to turing */
		qcom,smem-states = <&cdsp_smp2p_out 0>;
		qcom,smem-state-names = "qcom,force-stop";

		mboxes = <&qmp_aop 0>;
		mbox-names = "cdsp-pil";
	};
};

#include "sdmmagpie-pinctrl.dtsi"
#include "sdmmagpie-gdsc.dtsi"
#include "sdmmagpie-qupv3.dtsi"
#include "sdmmagpie-thermal.dtsi"

&pcie_0_gdsc {
	status = "ok";
};

&pcie_tbu_gdsc {
	status = "ok";
};

&usb30_prim_gdsc {
	status = "ok";
};

&ufs_phy_gdsc {
	status = "ok";
};

&hlos1_vote_aggre_noc_mmu_audio_tbu_gdsc {
	status = "ok";
};

&hlos1_vote_aggre_noc_mmu_pcie_tbu_gdsc {
	status = "ok";
};

&hlos1_vote_aggre_noc_mmu_tbu1_gdsc {
	status = "ok";
};

&hlos1_vote_aggre_noc_mmu_tbu2_gdsc {
	status = "ok";
};

&hlos1_vote_mmnoc_mmu_tbu_hf0_gdsc {
	status = "ok";
};

&hlos1_vote_mmnoc_mmu_tbu_hf1_gdsc {
	status = "ok";
};

&hlos1_vote_mmnoc_mmu_tbu_sf_gdsc {
	status = "ok";
};

&bps_gdsc {
	status = "ok";
};

&ife_0_gdsc {
	status = "ok";
};

&ife_1_gdsc {
	status = "ok";
};

&ipe_0_gdsc {
	status = "ok";
};

&ipe_1_gdsc {
	status = "ok";
};

&titan_top_gdsc {
	status = "ok";
};

&mdss_core_gdsc {
	status = "ok";
};

&gpu_cx_gdsc {
	status = "ok";
};

&gpu_gx_gdsc {
	status = "ok";
};

&mvsc_gdsc {
	status = "ok";
};

&mvs0_gdsc {
	status = "ok";
};

&mvs1_gdsc {
	status = "ok";
};

&npu_core_gdsc {
	status = "ok";
};

#include "sdmmagpie-ion.dtsi"
#include "msm-arm-smmu-sdmmagpie.dtsi"
#include "sdmmagpie-pm.dtsi"
#include "pm6150.dtsi"
#include "pm6150l.dtsi"
#include "sdmmagpie-regulator.dtsi"
